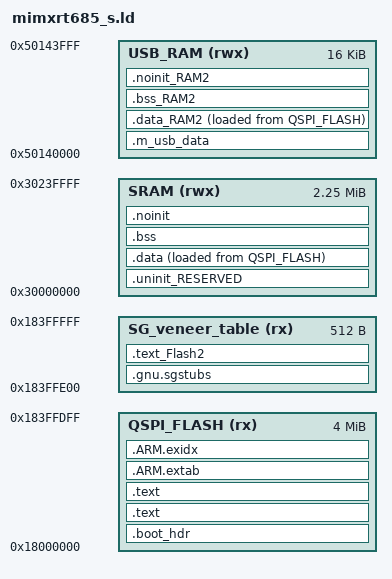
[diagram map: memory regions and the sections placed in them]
MEMORY
{
  /* Define each memory region */
  QSPI_FLASH (rx) : ORIGIN = 0x18000000, LENGTH = 0x3FFE00 /* 4M bytes (alias Flash) */  
  SG_veneer_table (rx) : ORIGIN = 0x183FFE00, LENGTH = 0x200 /* 512 bytes (alias Flash2) */
  SRAM (rwx) : ORIGIN = 0x30000000, LENGTH = 0x240000 /* 2.25M bytes (alias RAM) */  
  USB_RAM (rwx) : ORIGIN = 0x50140000, LENGTH = 0x4000 /* 16K bytes (alias RAM2) */  
}

ENTRY(_kernel_start)

SECTIONS
{
    /* Place TrustZone Secure Gateway veneers in 'SG_veneer_table' memory */
    .gnu.sgstubs : ALIGN (32)
    {
        . = ALIGN(32);
        _start_sg = .;
        *(.gnu.sgstubs*)
        . = ALIGN(32);
        _end_sg = .;
    } > SG_veneer_table
    .text_Flash2 : ALIGN(4)
    {
       FILL(0xff)
        *(.text_Flash2) /* for compatibility with previous releases */
        *(.text_SG_veneer_table) /* for compatibility with previous releases */
        *(.text.$Flash2)
        *(.text.$SG_veneer_table)
        *(.text_Flash2.*) /* for compatibility with previous releases */
        *(.text_SG_veneer_table.*) /* for compatibility with previous releases */
        *(.text.$Flash2.*)
        *(.text.$SG_veneer_table.*)
        *(.rodata.$Flash2)
        *(.rodata.$SG_veneer_table)
        *(.rodata.$Flash2.*)
        *(.rodata.$SG_veneer_table.*)
    } > SG_veneer_table

    /* Image Vector Table and Boot Data for booting from external flash */
    .boot_hdr : ALIGN(4)
    {
        FILL(0x00)
        __boot_hdr_start__ = ABSOLUTE(.) ;
        . = 0x400 ;
        __flash_conf_hdr_start__ = ABSOLUTE(.) ;
        KEEP(*(.flash_conf))
        __flash_conf_hdr_end__ = ABSOLUTE(.) ;
        . = 0x1000 ;
         __boot_hdr_end__ = ABSOLUTE(.) ;
    } >QSPI_FLASH

    /* MAIN TEXT SECTION */
    .text : ALIGN(4)
    {
        FILL(0xff)
        __vectors_start__ = ABSOLUTE(.) ;
        KEEP(*(.vector))
        /* Global Section Table */
        . = ALIGN(4) ;
        __section_table_start = .;
        __data_section_table = .;
        LONG(LOADADDR(.data));
        LONG(    ADDR(.data));
        LONG(  SIZEOF(.data));
        LONG(LOADADDR(.data_RAM2));
        LONG(    ADDR(.data_RAM2));
        LONG(  SIZEOF(.data_RAM2));
        __data_section_table_end = .;
        __bss_section_table = .;
        LONG(    ADDR(.bss));
        LONG(  SIZEOF(.bss));
        LONG(    ADDR(.bss_RAM2));
        LONG(  SIZEOF(.bss_RAM2));
        __bss_section_table_end = .;
        __section_table_end = . ;
        /* End of Global Section Table */

        *(.after_vectors*)

        *(.target_enter_fbb)
        PROVIDE(__target_enter_fbb_end = .);
    } > QSPI_FLASH

    .text : ALIGN(4)
    {
       *(.text*)
       *(.rodata .rodata.* .constdata .constdata.*)
       KEEP(*(.empty.*))
       . = ALIGN(4);
    } > QSPI_FLASH
    /*
     * for exception handling/unwind - some Newlib functions (in common
     * with C++ and STDC++) use this.
     */
    .ARM.extab : ALIGN(4)
    {
        *(.ARM.extab* .gnu.linkonce.armextab.*)
    } > QSPI_FLASH

    .ARM.exidx : ALIGN(4)
    {
        __exidx_start = .;
        *(.ARM.exidx* .gnu.linkonce.armexidx.*)
        __exidx_end = .;
    } > QSPI_FLASH
 
    _etext = .;
        
 
    /* USB_RAM */
    .m_usb_data (NOLOAD) :
    {
        *(m_usb_global)
    } > USB_RAM AT> USB_RAM
    /* DATA section for USB_RAM */

    .data_RAM2 : ALIGN(4)
    {
        FILL(0xff)
        PROVIDE(__start_data_RAM2 = .) ;
        PROVIDE(__start_data_USB_RAM = .) ;
        *(.ramfunc.$RAM2)
        *(.ramfunc.$USB_RAM)
        *(.data.$RAM2)
        *(.data.$USB_RAM)
        *(.data.$RAM2.*)
        *(.data.$USB_RAM.*)
        . = ALIGN(4) ;
        PROVIDE(__end_data_RAM2 = .) ;
        PROVIDE(__end_data_USB_RAM = .) ;
     } > USB_RAM AT>QSPI_FLASH

    /* MAIN DATA SECTION */
    .uninit_RESERVED (NOLOAD) : ALIGN(4)
    {
        _start_uninit_RESERVED = .;
        KEEP(*(.bss.$RESERVED*))
       . = ALIGN(4) ;
        _end_uninit_RESERVED = .;
    } > SRAM AT> SRAM

    /* Main DATA section (SRAM) */
    .data : ALIGN(4)
    {
       FILL(0xff)
       _data = . ;
       PROVIDE(__start_data_RAM = .) ;
       PROVIDE(__start_data_SRAM = .) ;
       *(vtable)
       *(.ramfunc*)
       KEEP(*(CodeQuickAccess))
       KEEP(*(DataQuickAccess))
       *(RamFunction)
       *(.data*)
       . = ALIGN(4) ;
       _edata = . ;
       PROVIDE(__end_data_RAM = .) ;
       PROVIDE(__end_data_SRAM = .) ;
    } > SRAM AT>QSPI_FLASH

    /* BSS section for USB_RAM */
    .bss_RAM2 : ALIGN(4)
    {
       PROVIDE(__start_bss_RAM2 = .) ;
       PROVIDE(__start_bss_USB_RAM = .) ;
       *(.bss.$RAM2)
       *(.bss.$USB_RAM)
       *(.bss.$RAM2.*)
       *(.bss.$USB_RAM.*)
       . = ALIGN (. != 0 ? 4 : 1) ; /* avoid empty segment */
       PROVIDE(__end_bss_RAM2 = .) ;
       PROVIDE(__end_bss_USB_RAM = .) ;
    } > USB_RAM AT> USB_RAM

    /* MAIN BSS SECTION */
    .bss : ALIGN(4)
    {
        _bss = .;
        PROVIDE(__start_bss_RAM = .) ;
        PROVIDE(__start_bss_SRAM = .) ;
        *(.bss*)
        *(COMMON)
        . = ALIGN(4) ;
        _ebss = .;
        PROVIDE(__end_bss_RAM = .) ;
        PROVIDE(__end_bss_SRAM = .) ;
        PROVIDE(end = .);
    } > SRAM AT> SRAM

    /* NOINIT section for USB_RAM */
    .noinit_RAM2 (NOLOAD) : ALIGN(4)
    {
       PROVIDE(__start_noinit_RAM2 = .) ;
       PROVIDE(__start_noinit_USB_RAM = .) ;
       *(.noinit.$RAM2)
       *(.noinit.$USB_RAM)
       *(.noinit.$RAM2.*)
       *(.noinit.$USB_RAM.*)
       . = ALIGN(4) ;
       PROVIDE(__end_noinit_RAM2 = .) ;
       PROVIDE(__end_noinit_USB_RAM = .) ;
    } > USB_RAM AT> USB_RAM

    /* DEFAULT NOINIT SECTION */
    .noinit (NOLOAD): ALIGN(4)
    {
        _noinit = .;
        PROVIDE(__start_noinit_RAM = .) ;
        PROVIDE(__start_noinit_SRAM = .) ;
        *(.noinit*)
         . = ALIGN(4) ;
        _end_noinit = .;
       PROVIDE(__end_noinit_RAM = .) ;
       PROVIDE(__end_noinit_SRAM = .) ;        
    } > SRAM AT> SRAM
}
